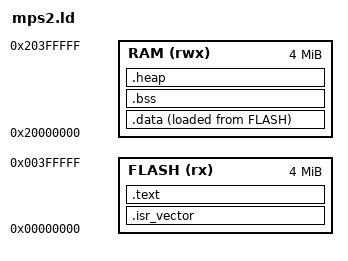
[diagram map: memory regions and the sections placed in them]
MEMORY
{
    FLASH (rx)  : ORIGIN = 0x00000000, LENGTH = 4M
    RAM   (rwx) : ORIGIN = 0x20000000, LENGTH = 4M
}

_estack = ORIGIN(RAM) + LENGTH(RAM);

ENTRY(Reset_Handler)

SECTIONS
{
    .isr_vector :
    {
        . = ALIGN(4);
        KEEP(*(.isr_vector))
        . = ALIGN(4);
    } > FLASH

    .text :
    {
        . = ALIGN(4);
        *(.text*)
        *(.rodata*)
        . = ALIGN(4);
    } > FLASH

    _sidata = LOADADDR(.data);

    .data :
    {
        . = ALIGN(4);
        _sdata = .;
        *(.data*)
        . = ALIGN(4);
        _edata = .;
    } > RAM AT > FLASH

    .bss :
    {
        . = ALIGN(4);
        _sbss = .;
        *(.bss*)
        *(COMMON)
        . = ALIGN(4);
        _ebss = .;
        _end = .;
    } > RAM

    .heap (NOLOAD) :
    {
        . = ALIGN(8);
        _heap_start = .;
        . += 256K;
        _heap_end = .;
    } > RAM
}
